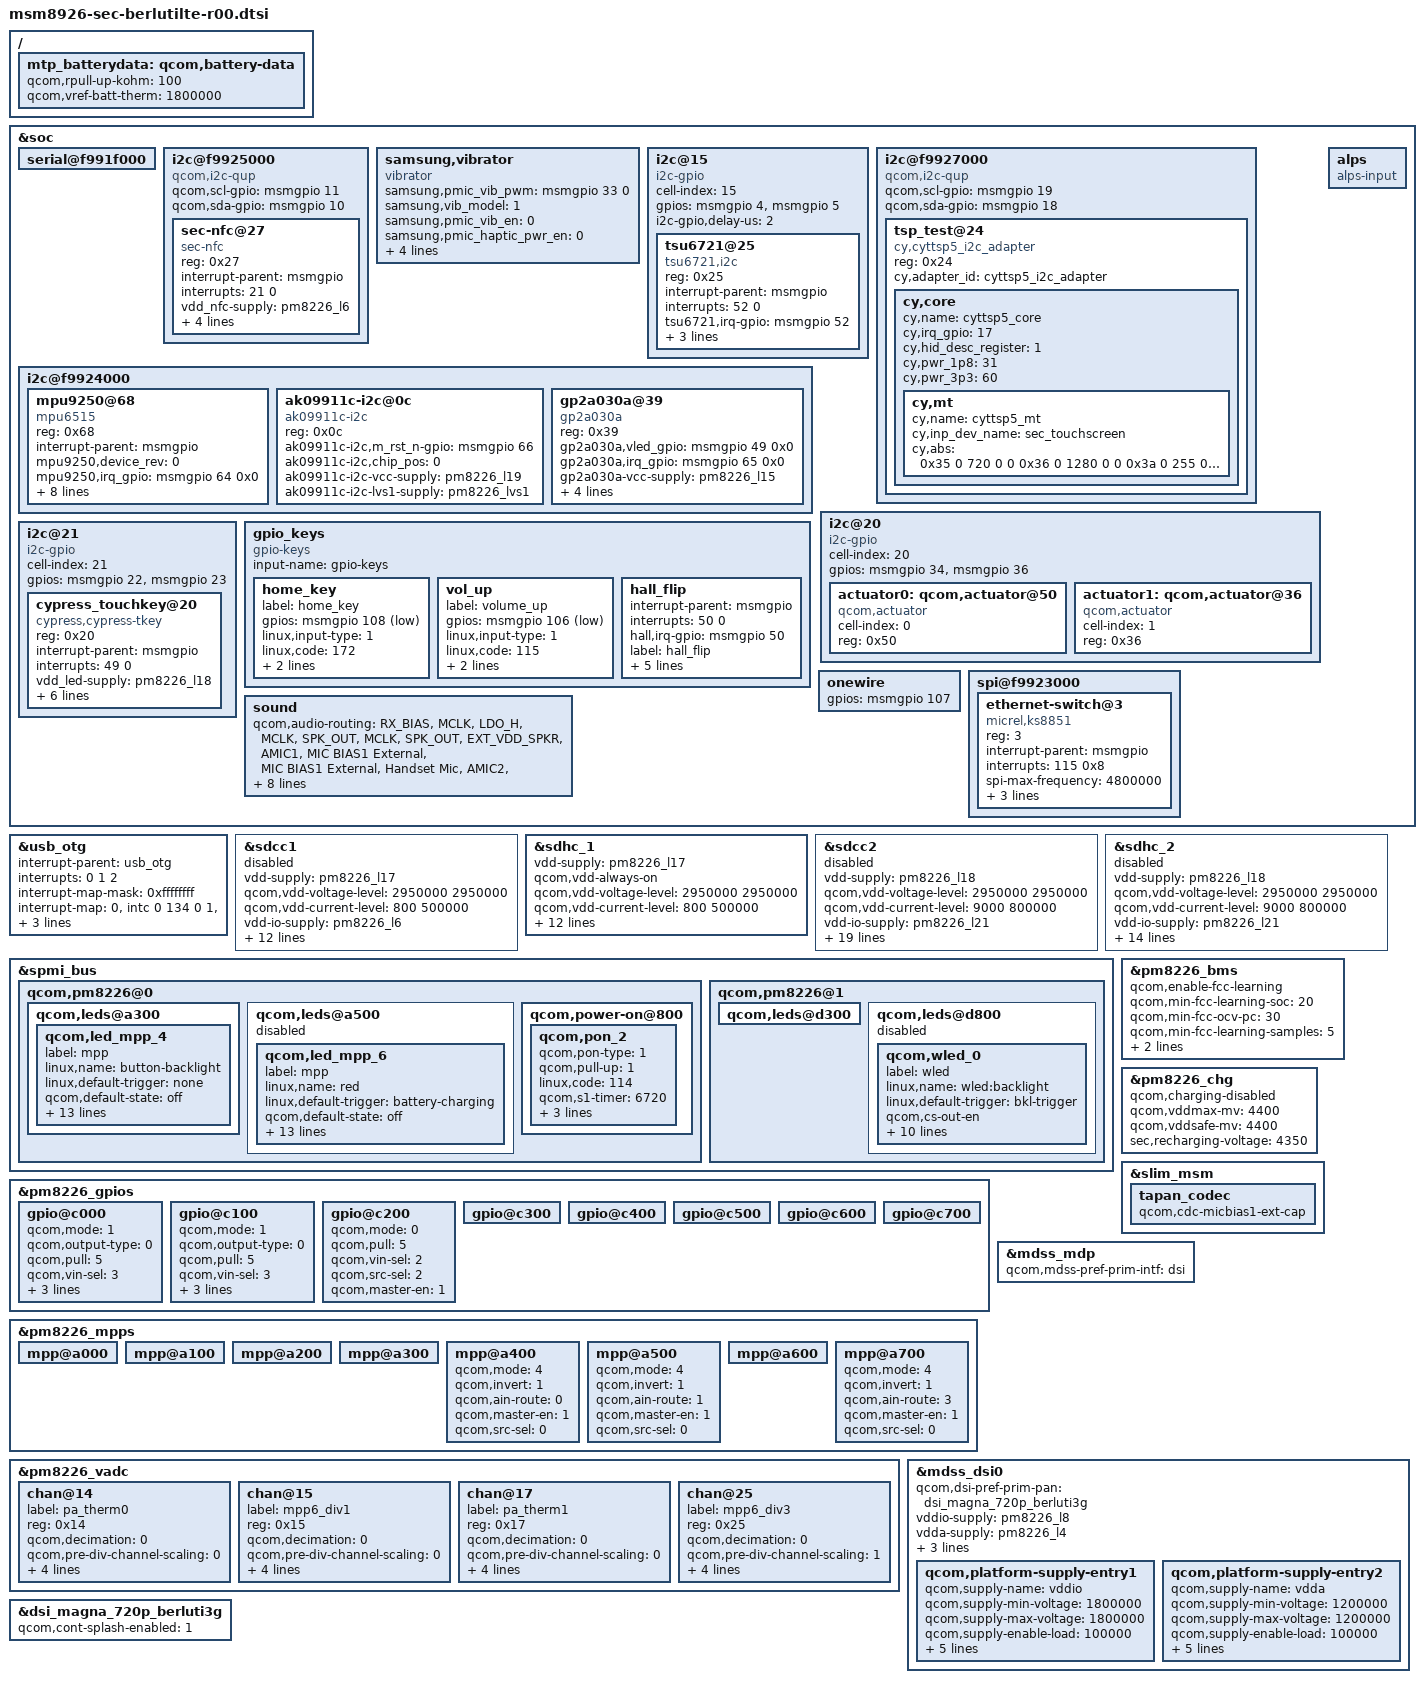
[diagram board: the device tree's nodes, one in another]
/* Copyright (c) 2013, The Linux Foundation. All rights reserved.
 *
 * This program is free software; you can redistribute it and/or modify
 * it under the terms of the GNU General Public License version 2 and
 * only version 2 as published by the Free Software Foundation.
 *
 * This program is distributed in the hope that it will be useful,
 * but WITHOUT ANY WARRANTY; without even the implied warranty of
 * MERCHANTABILITY or FITNESS FOR A PARTICULAR PURPOSE.  See the
 * GNU General Public License for more details.
 */

/include/ "msm8226-camera-sensor-mtp-berluti3g_eur.dtsi"
/include/ "dsi_panel_magna_ea8061v_octa_720p_video.dtsi"
/include/ "msm8928-w1.dtsi"

&soc {
	serial@f991f000 {
		status = "ok";
	}; 
	
	i2c@f9925000 {
		compatible = "qcom,i2c-qup";
		qcom,scl-gpio = <&msmgpio 11 0>;
		qcom,sda-gpio = <&msmgpio 10 0>;
		status = "okay";
		sec-nfc@27 {
			compatible = "sec-nfc";
			reg = <0x27>;
			interrupt-parent = <&msmgpio>;
			interrupts = <21 0>;
			vdd_nfc-supply = <&pm8226_l6>;
			sec-nfc,firm-gpio = <&msmgpio 62 0x00>;
			sec-nfc,ven-gpio = <&msmgpio 20 0x00>;
			sec-nfc,irq-gpio = <&msmgpio 21 0x01>;
			nfc_ldo-supply = <&pm8226_l22>;
		};
	};

	samsung,vibrator {
		compatible = "vibrator";
		samsung,pmic_vib_pwm = <&msmgpio 33 0>;
		samsung,vib_model = <1>;
		samsung,pmic_vib_en = <0>;
		samsung,pmic_haptic_pwr_en = <0>;
		samsung,is_pmic_vib_pwm = <0>;
		samsung,pwm_period_us = <40>;
		samsung,duty_us = <36>;
		samsung,drv2603_en = <&msmgpio 111 0>;
		status = "ok";
	};

	i2c@15 {
		cell-index = <15>;
		compatible = "i2c-gpio";
		gpios = <&msmgpio 4 0 /* sda */
			 &msmgpio 5 0 /* scl */
			 >;
		i2c-gpio,delay-us = <2>;
		#address-cells = <1>;
		#size-cells = <0>;

		tsu6721@25{
			compatible = "tsu6721,i2c";
			reg = <0x25>;
			interrupt-parent = <&msmgpio>;
			interrupts= <52 0>;
			tsu6721,irq-gpio = <&msmgpio 52 0x00>;
			tsu6721,gpio-sda = <&msmgpio 4 0x00>;
			tsu6721,gpio-scl = <&msmgpio 5 0x00>;
			tsu6721,uarton-gpio = <&msmgpio 109 0x00>;
		};
	};

	i2c@f9924000 { /* BLSP1 QUP2 */
		mpu9250@68 {
			compatible = "mpu6515";
			reg = <0x68>;
			interrupt-parent = <&msmgpio>;
			mpu9250,device_rev = <0>;
			mpu9250,irq_gpio = <&msmgpio 64 0x0>;
			mpu9250,int_config = <0>;
			mpu9250,level_shifter = <0>;
			mpu9250,sec_slave_type = <0>;
			mpu9250,sec_slave_id = <0>;
			mpu9250,orientation = <1 2 1 2 1 1 1 1 0>;
			mpu9250,key = <211 22 205 7
				217 186 151 55
				206 254 35 144
				225 102 47 50>;
			mpu9250-lvs1-supply = <&pm8226_lvs1>;
		};
		ak09911c-i2c@0c {
			compatible = "ak09911c-i2c";
			reg = <0x0c>;
			ak09911c-i2c,m_rst_n-gpio = <&msmgpio 66 0x0>;
			ak09911c-i2c,chip_pos = <0>;
			ak09911c-i2c-vcc-supply = <&pm8226_l19>;
			ak09911c-i2c-lvs1-supply = <&pm8226_lvs1>;
		};
		gp2a030a@39 {
			compatible = "gp2a030a";
			reg = <0x39>;
			gp2a030a,vled_gpio = <&msmgpio 49 0x0>;
			gp2a030a,irq_gpio = <&msmgpio 65 0x0>;
			gp2a030a-vcc-supply = <&pm8226_l15>;
			gp2a030a-lvs1-supply = <&pm8226_lvs1>;
			qcom,gp2a030a-vcc-voltage-level = <2800000 2800000>;
			qcom,gp2a030a-vcc-always-on;
		};
	};

	i2c@f9927000{ /* BLSP1 QUP5 Hardware ID BLSP5 */
		compatible = "qcom,i2c-qup";
		qcom,scl-gpio = <&msmgpio 19 0>;
		qcom,sda-gpio = <&msmgpio 18 0>;
		tsp_test@24 {
				compatible = "cy,cyttsp5_i2c_adapter";
				reg = <0x24>; /*slave address*/
				cy,adapter_id = "cyttsp5_i2c_adapter";

				cy,core { 
					cy,name = "cyttsp5_core";

					cy,irq_gpio = <17>;
					cy,hid_desc_register = <1>;
					cy,pwr_1p8 = <31>; /*<&msmgpio 31 0x01>; */ /*Touch En 1 gpio*/
					cy,pwr_3p3 = <60>;  /* <&msmgpio 60 0x01>; */ /* Touch En2 gpio */

					cy,mt { 
						cy,name = "cyttsp5_mt";
						cy,inp_dev_name = "sec_touchscreen";					
						cy,abs =
							/* ABS_MT_POSITION_X, CY_ABS_MIN_X, CY_ABS_MAX_X, 0, 0 */
							<0x35 0 720 0 0
							/* ABS_MT_POSITION_Y, CY_ABS_MIN_Y, CY_ABS_MAX_Y, 0, 0 */
							0x36 0 1280 0 0
							/* ABS_MT_PRESSURE, CY_ABS_MIN_P, CY_ABS_MAX_P, 0, 0 */
							0x3a 0 255 0 0
							/* CY_IGNORE_VALUE, CY_ABS_MIN_W, CY_ABS_MAX_W, 0, 0 */
							0xffff 0 255 0 0
							/* ABS_MT_TRACKING_ID, CY_ABS_MIN_T, CY_ABS_MAX_T, 0, 0 */
							0x39 0 15 0 0
							/* ABS_MT_TOUCH_MAJOR, 0, 255, 0, 0 */
							0x30 0 255 0 0
							/* ABS_MT_TOUCH_MINOR, 0, 255, 0, 0 */
							0x31 0 255 0 0
							/* ABS_MT_ORIENTATION, -128, 127, 0, 0 */
							0x34 0xfffffed7 127 0 0
							/* ABS_MT_TOOL_TYPE, 0, MT_TOOL_MAX, 0, 0 */
							0x37 0 1 0 0>;
					};
				};
			};
	};

	i2c@20 {
		cell-index = <20>;
		compatible = "i2c-gpio";
		gpios = <&msmgpio 34 0 /* sda */
			&msmgpio 36 0 /* scl */>;

		actuator0: qcom,actuator@50 {
			compatible = "qcom,actuator";
			cell-index = <0>;
			reg = <0x50>;
		};
		actuator1: qcom,actuator@36 {
			compatible = "qcom,actuator";
			cell-index = <1>;
			reg = <0x36>;
		};
	};

	i2c@21 {
		cell-index = <21>;
		compatible = "i2c-gpio";
		gpios = <&msmgpio 22 0 /* sda */
		&msmgpio 23 0 /* scl */
		>;
		#address-cells = <1>;
		#size-cells = <0>;

		cypress_touchkey@20 {
				compatible = "cypress,cypress-tkey";
				reg = <0x20>; /*slave address*/
				interrupt-parent = <&msmgpio>;
				interrupts = <49 0>; /* Touch int gpio */
				vdd_led-supply = <&pm8226_l18>;
				vcc_en-supply = <&pm8226_l27>;
				cypress,scl-gpio = <&msmgpio 23 0x00>;
				cypress,sda-gpio = <&msmgpio 22 0x00>;
				cypress,irq-gpio = <&msmgpio 49 0x00>;
				/* cypress,touchkey_id-gpio = <&msmgpio 101 0x00>; */
				cypress,tkey-keycodes = <254 158>;
				cypress,i2c-pull-up = <1>;
		};
	};
	gpio_keys {
		compatible = "gpio-keys";
		input-name = "gpio-keys";

		home_key {
			label = "home_key";
			gpios = <&msmgpio 108 0x1>;
			linux,input-type = <1>;
			linux,code = <172>;
			gpio-key,wakeup;
			debounce-interval = <15>;
		};

		vol_up {
			label = "volume_up";
			gpios = <&msmgpio 106 0x1>;
			linux,input-type = <1>;
			linux,code = <115>;
			gpio-key,wakeup;
			debounce-interval = <15>;
		};

		hall_flip {
			interrupt-parent = <&msmgpio>;
			interrupts = <50 0>;
			hall,irq-gpio = <&msmgpio 50 0x00>;

			label = "hall_flip";
			gpios = <&msmgpio 50 0>;
			linux,input-type = <1>;
			linux,code = <0x15>;
			gpio-key,wakeup;
			debounce-interval = <15>;
		};
	};
	alps {
			compatible = "alps-input";
	};
	onewire {
		gpios = <&msmgpio 107 0x00>;
	};
	spi@f9923000 {
		ethernet-switch@3 {
			compatible = "micrel,ks8851";
			reg = <3>;
			interrupt-parent = <&msmgpio>;
			interrupts = <115 0x8>;
			spi-max-frequency = <4800000>;
			rst-gpio = <&msmgpio 114 0>;
			vdd-io-supply = <&pm8226_lvs1>;
			vdd-phy-supply = <&pm8226_lvs1>;
		};
	};

	sound {
		qcom,audio-routing =
			"RX_BIAS", "MCLK",
			"LDO_H", "MCLK",
			"SPK_OUT", "MCLK",
			"SPK_OUT", "EXT_VDD_SPKR",
			"AMIC1", "MIC BIAS1 External",
			"MIC BIAS1 External", "Handset Mic",
			"AMIC2", "MIC BIAS2 External",
			"MIC BIAS2 External", "Headset Mic",
			"AMIC3", "MIC BIAS3 External",
			"MIC BIAS3 External", "Sub Mic",
			"AMIC4", "MIC BIAS2 External",
			"MIC BIAS2 External", "ANCRight Headset Mic",
			"AMIC5", "MIC BIAS2 External",
			"MIC BIAS2 External", "ANCLeft Headset Mic";

		qcom,cdc-mclk-gpios = <&pm8226_gpios 1 0>;
		/*qcom,cdc-vdd-spkr-gpios = <&pm8226_gpios 2 0>;*/
	};
};

&usb_otg {
	#address-cells = <0>;
	interrupt-parent = <&usb_otg>;
	interrupts = <0 1 2>;
	#interrupt-cells = <1>;
	interrupt-map-mask = <0xffffffff>;
	interrupt-map = <0 &intc 0 134 0
			1 &intc 0 140 0
			2 &spmi_bus 0x0 0x0 0x9 0x0>;
	interrupt-names = "core_irq", "async_irq", "pmic_id_irq";

	qcom,hsusb-otg-mode = <3>;
	vbus_otg-supply = <&pm8226_chg_otg>;
};

&sdcc1 {
	vdd-supply = <&pm8226_l17>;
	qcom,vdd-voltage-level = <2950000 2950000>;
	qcom,vdd-current-level = <800 500000>;

	vdd-io-supply = <&pm8226_l6>;
	qcom,vdd-io-always-on;
	qcom,vdd-io-voltage-level = <1800000 1800000>;
	qcom,vdd-io-current-level = <250 154000>;

	qcom,pad-pull-on = <0x0 0x3 0x3>; /* no-pull, pull-up, pull-up */
	qcom,pad-pull-off = <0x0 0x3 0x3>; /* no-pull, pull-up, pull-up */
	qcom,pad-drv-on = <0x4 0x4 0x4>; /* 10mA, 10mA, 10mA */
	qcom,pad-drv-off = <0x0 0x0 0x0>; /* 2mA, 2mA, 2mA */

	qcom,clk-rates = <400000 25000000 50000000 100000000 200000000>;
	qcom,sup-voltages = <2950 2950>;

	qcom,bus-speed-mode = "HS200_1p8v", "DDR_1p8v";
	qcom,nonremovable;

	status = "disabled";
};

&sdhc_1 {
	vdd-supply = <&pm8226_l17>;
	qcom,vdd-always-on;
	qcom,vdd-voltage-level = <2950000 2950000>;
	qcom,vdd-current-level = <800 500000>;

	vdd-io-supply = <&pm8226_l6>;
	qcom,vdd-io-always-on;
	qcom,vdd-io-voltage-level = <1800000 1800000>;
	qcom,vdd-io-current-level = <250 154000>;

	qcom,pad-pull-on = <0x0 0x3 0x3>; /* no-pull, pull-up, pull-up */
	qcom,pad-pull-off = <0x0 0x3 0x3>; /* no-pull, pull-up, pull-up */
	qcom,pad-drv-on = <0x4 0x4 0x4>; /* 10mA, 10mA, 10mA */
	qcom,pad-drv-off = <0x0 0x0 0x0>; /* 2mA, 2mA, 2mA */

	qcom,clk-rates = <400000 25000000 50000000 100000000 200000000>;
	qcom,bus-speed-mode = "HS200_1p8v", "DDR_1p8v";
	qcom,nonremovable;

	status = "ok";
};

&sdcc2 {
	vdd-supply = <&pm8226_l18>;
	qcom,vdd-voltage-level = <2950000 2950000>;
	qcom,vdd-current-level = <9000 800000>;

	vdd-io-supply = <&pm8226_l21>;
	qcom,vdd-io-voltage-level = <1800000 2950000>;
	qcom,vdd-io-current-level = <6 22000>;

	qcom,pad-pull-on = <0x0 0x3 0x3>; /* no-pull, pull-up, pull-up */
	qcom,pad-pull-off = <0x0 0x3 0x3>; /* no-pull, pull-up, pull-up */
	qcom,pad-drv-on = <0x4 0x4 0x4>; /* 10mA, 10mA, 10mA */
	qcom,pad-drv-off = <0x0 0x0 0x0>; /* 2mA, 2mA, 2mA */

	qcom,clk-rates = <400000 25000000 50000000 100000000 200000000>;
	qcom,sup-voltages = <2950 2950>;

	qcom,xpc;
	qcom,bus-speed-mode = "SDR12", "SDR25", "SDR50", "DDR50", "SDR104";
	qcom,current-limit = <600>; #address-cells = <0>; interrupt-parent = <&sdcc2>;
	interrupts = <0 1 2>;
	#interrupt-cells = <1>;
	interrupt-map-mask = <0xffffffff>;
	interrupt-map = <0 &intc 0 125 0
			1 &intc 0 220 0
			2 &msmgpio 38 0x3>;
	interrupt-names = "core_irq", "bam_irq", "status_irq";
	cd-gpios = <&msmgpio 38 0x1>;

	status = "disabled";
};

&sdhc_2 {
	vdd-supply = <&pm8226_l18>;
	qcom,vdd-voltage-level = <2950000 2950000>;
	qcom,vdd-current-level = <9000 800000>;

	vdd-io-supply = <&pm8226_l21>;
	qcom,vdd-io-voltage-level = <1800000 2950000>;
	qcom,vdd-io-current-level = <6 22000>;

	qcom,pad-pull-on = <0x0 0x3 0x3>; /* no-pull, pull-up, pull-up */
	qcom,pad-pull-off = <0x0 0x1 0x1>; /* no-pull, pull-down, pull-down */
	qcom,pad-drv-on = <0x4 0x4 0x4>; /* 10mA, 10mA, 10mA */
	qcom,pad-drv-off = <0x0 0x0 0x0>; /* 2mA, 2mA, 2mA */

	qcom,clk-rates = <400000 25000000 50000000 100000000 200000000>;

	#address-cells = <0>;
	interrupt-parent = <&sdhc_2>;
	interrupts = <0 1 2>;
	#interrupt-cells = <1>;
	interrupt-map-mask = <0xffffffff>;
	interrupt-map = <0 &intc 0 125 0
			1 &intc 0 221 0
			2 &msmgpio 38 0x3>;
	interrupt-names = "hc_irq", "pwr_irq", "status_irq";
	cd-gpios = <&msmgpio 38 0x1>;

	status = "disabled";
};

&spmi_bus {
	qcom,pm8226@0 {
		/*qcom,leds@a100 {   this node is not used.
			status = "disabled";
			qcom,led_mpp_2 {
				label = "mpp";
				linux,name = "green";
				linux,default-trigger = "battery-full";
				qcom,default-state = "off";
				qcom,max-current = <40>;
				qcom,current-setting = <5>;
				qcom,id = <6>;
				qcom,mode = "manual";
				qcom,source-sel = <1>;
				qcom,mode-ctrl = <0x60>;
			};
		};*/
		qcom,leds@a300 {
			status = "okay";
			qcom,led_mpp_4 {
				label = "mpp";
				linux,name = "button-backlight";
				linux,default-trigger = "none";
				qcom,default-state = "off";
				qcom,max-current = <40>;
				qcom,current-setting = <40>;
				qcom,id = <6>;
				qcom,mode = "pwm";
				qcom,pwm-us = <1000>;
				qcom,source-sel = <8>;
				qcom,mode-ctrl = <0x60>;
				qcom,pwm-channel = <0>;
				qcom,start-idx = <1>;
				qcom,ramp-step-ms = <120>;
				qcom,duty-pcts = [00 00 00 00 00
						  00 00 00 00 00
						  50 00 00 00 00
						  00 00 00 00 00
						  00];
				qcom,use-blink;
			};
		};
		qcom,leds@a500 {
			status = "disabled";
			qcom,led_mpp_6 {
				label = "mpp";
				linux,name = "red";
				linux,default-trigger = "battery-charging";
				qcom,default-state = "off";
				qcom,max-current = <40>;
				qcom,current-setting = <5>;
				qcom,id = <6>;
				qcom,mode = "pwm";
				qcom,pwm-us = <1000>;
				qcom,mode-ctrl = <0x60>;
				qcom,source-sel = <10>;
				qcom,pwm-channel = <5>;
				qcom,start-idx = <1>;
				qcom,ramp-step-ms = <120>;
				qcom,duty-pcts = [00 00 00 00 00
						  00 00 00 00 00
						  50 00 00 00 00
						  00 00 00 00 00
						  00];
				qcom,use-blink;
			};
		};
		qcom,power-on@800 {
			qcom,pon_2 {
				qcom,pon-type = <1>;
				qcom,pull-up = <1>;
				linux,code = <114>;
				qcom,s1-timer = <6720>;
				qcom,s2-timer = <2000>;
				qcom,s2-type = <7>;
				qcom,support-reset = <1>;
			};
		};
	};

	qcom,pm8226@1 {
                qcom,leds@d300 {
                        status = "okay";
                };

		qcom,leds@d800 {
			status = "disabled";/*If WLED is not used for Backlight control*/
			qcom,wled_0 {		/*for TFT Panel, this to be disabled */
				label = "wled";
				linux,name = "wled:backlight";
				linux,default-trigger = "bkl-trigger";
				qcom,cs-out-en;
				qcom,op-fdbck = <1>;
				qcom,default-state = "off";
				qcom,max-current = <20>;
				qcom,ctrl-delay-us = <0>;
				qcom,boost-curr-lim = <3>;
				qcom,cp-sel = <0>;
				qcom,switch-freq = <11>;
				qcom,ovp-val = <0>;
				qcom,num-strings = <1>;
				qcom,id = <0>;
			};
		};
	};
};

&pm8226_gpios {
	gpio@c000 { /* GPIO 1 */
		/* XO_PMIC_CDC_MCLK enable for tapan codec */
		qcom,mode = <1>;		/* Digital output */
		qcom,output-type = <0>;	/* CMOS logic */
		qcom,pull = <5>;		/* QPNP_PIN_PULL_NO*/
		qcom,vin-sel = <3>;		/* QPNP_PIN_VIN3 */
		qcom,out-strength = <3>;/* QPNP_PIN_OUT_STRENGTH_HIGH */
		qcom,src-sel = <2>;		/* QPNP_PIN_SEL_FUNC_1 */
		qcom,master-en = <1>;	/* Enable GPIO */
	};

	gpio@c100 { /* GPIO 2 */
		qcom,mode = <1>;
		qcom,output-type = <0>;
		qcom,pull = <5>;
		qcom,vin-sel = <3>;
		qcom,out-strength = <3>;
		qcom,src-sel = <2>;
		qcom,master-en = <1>;
	};

	gpio@c200 { /* GPIO 3 */
		qcom,mode = <0>;		/* QPNP_PIN_MODE_DIG_IN */
		qcom,pull = <5>;		/* QPNP_PIN_PULL_NO */
		qcom,vin-sel = <2>;		/* QPNP_PIN_VIN2 */
		qcom,src-sel = <2>;		/* QPNP_PIN_SEL_FUNC_1 */
		qcom,master-en = <1>;
	};

	gpio@c300 { /* GPIO 4 */
	};

	gpio@c400 { /* GPIO 5 */
	};

	gpio@c500 { /* GPIO 6 */
	};

	gpio@c600 { /* GPIO 7 */
	};

	gpio@c700 { /* GPIO 8 */
	};
};

&pm8226_mpps {
	mpp@a000 { /* MPP 1 */
	};

	mpp@a100 { /* MPP 2 */
	};

	mpp@a200 { /* MPP 3 */
	};

	mpp@a300 { /* MPP 4 */
	};

	mpp@a400 { /* MPP 5 */
		/* PA_THERM0 config */
		qcom,mode = <4>; /* AIN input */
		qcom,invert = <1>; /* Enable MPP */
		qcom,ain-route = <0>; /* AMUX 5 */
		qcom,master-en = <1>;
		qcom,src-sel = <0>; /* Function constant */
	};

	mpp@a500 { /* MPP 6 */
		qcom,mode = <4>; /* AIN input */
		qcom,invert = <1>; /* Enable MPP */
		qcom,ain-route = <1>; /* AMUX 6 */
		qcom,master-en = <1>;
		qcom,src-sel = <0>; /* Function constant */
	};

	mpp@a600 { /* MPP 7 */
	};

	mpp@a700 { /* MPP 8 */
		/* PA_THERM1 config */
		qcom,mode = <4>; /* AIN input */
		qcom,invert = <1>; /* Enable MPP */
		qcom,ain-route = <3>; /* AMUX 8 */
		qcom,master-en = <1>;
		qcom,src-sel = <0>; /* Function constant */
	};
};

&pm8226_vadc {
	chan@14 {
		label = "pa_therm0";
		reg = <0x14>;
		qcom,decimation = <0>;
		qcom,pre-div-channel-scaling = <0>;
		qcom,calibration-type = "ratiometric";
		qcom,scale-function = <2>;
		qcom,hw-settle-time = <2>;
		qcom,fast-avg-setup = <0>;
	};
	chan@15 {
		label = "mpp6_div1";
		reg = <0x15>;
		qcom,decimation = <0>;
		qcom,pre-div-channel-scaling = <0>;
		qcom,calibration-type = "absolute";
		qcom,scale-function = <0>;
		qcom,hw-settle-time = <0>;
		qcom,fast-avg-setup = <0>;
	};

	chan@17 {
		label = "pa_therm1";
		reg = <0x17>;
		qcom,decimation = <0>;
		qcom,pre-div-channel-scaling = <0>;
		qcom,calibration-type = "ratiometric";
		qcom,scale-function = <2>;
		qcom,hw-settle-time = <2>;
		qcom,fast-avg-setup = <0>;
	};
	chan@25 {
		label = "mpp6_div3";
		reg = <0x25>;
		qcom,decimation = <0>;
		qcom,pre-div-channel-scaling = <1>;
		qcom,calibration-type = "absolute";
		qcom,scale-function = <0>;
		qcom,hw-settle-time = <0>;
		qcom,fast-avg-setup = <0>;
	};
};

/ {
	mtp_batterydata: qcom,battery-data {
		qcom,rpull-up-kohm = <100>;
		qcom,vref-batt-therm = <1800000>;

		/include/ "batterydata-palladium.dtsi"
		/include/ "batterydata-mtp-3000mah.dtsi"
	};
};

&pm8226_bms {
	status = "ok";
	qcom,enable-fcc-learning;
	qcom,min-fcc-learning-soc = <20>;
	qcom,min-fcc-ocv-pc = <30>;
	qcom,min-fcc-learning-samples = <5>;
	qcom,fcc-resolution = <10>;
	qcom,battery-data = <&mtp_batterydata>;
};

&pm8226_chg {
	qcom,charging-disabled;
	qcom,vddmax-mv = <4400>;
	qcom,vddsafe-mv = <4400>;
	sec,recharging-voltage = <4350>;

};

&slim_msm {
	tapan_codec {
		qcom,cdc-micbias1-ext-cap;
	};
};

&mdss_mdp {
	qcom,mdss-pref-prim-intf = "dsi";
};

&mdss_dsi0 {
	qcom,dsi-pref-prim-pan = <&dsi_magna_720p_berluti3g>;
	vddio-supply = <&pm8226_l8>;
	vdda-supply = <&pm8226_l4>;
	qcom,platform-bist-ctrl = [00 00 b1 ff			 /*!!!! BIST Ctrl settings */
				   00 00];
	qcom,platform-lane-config = [
	00 00 00 00 00 00 00 01 75 /* lane0 config */
	00 00 00 00 05 00 00 01 75 /* lane1 config */
	00 00 00 00 0a 00 00 01 75 /* lane2 config */
	00 00 00 00 0f 00 00 01 75 /* lane3 config */
	00 c0 00 00 00 00 00 01 97]; /* Clk ln config */
	qcom,platform-supply-entry1 {
		qcom,supply-name = "vddio";
		qcom,supply-min-voltage = <1800000>;
		qcom,supply-max-voltage = <1800000>;
		qcom,supply-enable-load = <100000>;
		qcom,supply-disable-load = <100>;
		qcom,supply-pre-on-sleep = <0>;
		qcom,supply-post-on-sleep = <0>;
		qcom,supply-pre-off-sleep = <0>;
		qcom,supply-post-off-sleep = <0>;
	};
	qcom,platform-supply-entry2 {
		qcom,supply-name = "vdda";
		qcom,supply-min-voltage = <1200000>;
		qcom,supply-max-voltage = <1200000>;
		qcom,supply-enable-load = <100000>;
		qcom,supply-disable-load = <100>;
		qcom,supply-pre-on-sleep = <0>;
		qcom,supply-post-on-sleep = <20>;
		qcom,supply-pre-off-sleep = <0>;
		qcom,supply-post-off-sleep = <0>;
	};
};

&dsi_magna_720p_berluti3g  {
	qcom,cont-splash-enabled = <1>;
};

